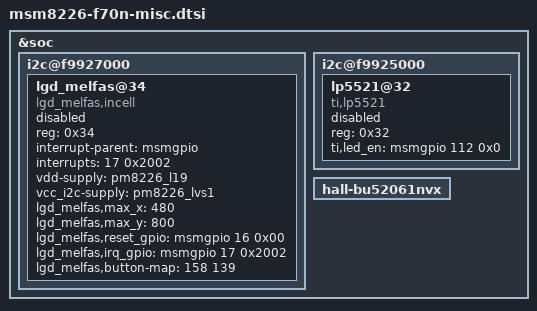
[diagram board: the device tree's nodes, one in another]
/* Copyright (c) 2012, Code Aurora Forum. All rights reserved.
 *
 * This program is free software; you can redistribute it and/or modify
 * it under the terms of the GNU General Public License version 2 and
 * only version 2 as published by the Free Software Foundation.
 *
 * This program is distributed in the hope that it will be useful,
 * but WITHOUT ANY WARRANTY; without even the implied warranty of
 * MERCHANTABILITY or FITNESS FOR A PARTICULAR PURPOSE.  See the
 * GNU General Public License for more details.
 */

&soc {
	i2c@f9927000 { /* BLSP1 QUP5 */
		lgd_melfas@34 {
			compatible = "lgd_melfas,incell";
			reg = <0x34>;
			interrupt-parent = <&msmgpio>;
			interrupts = <17 0x2002>;
			vdd-supply = <&pm8226_l19>;
			vcc_i2c-supply = <&pm8226_lvs1>;
			lgd_melfas,max_x = <480>;
			lgd_melfas,max_y = <800>;
			lgd_melfas,reset_gpio = <&msmgpio 16 0x00>;
			lgd_melfas,irq_gpio = <&msmgpio 17 0x2002>;
			lgd_melfas,button-map = <158 139>;
			status = "disable";
		};

	};

	i2c@f9925000 {
		lp5521@32 {
			compatible = "ti,lp5521";
			status = "disable";
			reg = <0x32>;
			ti,led_en = <&msmgpio 112 0x0>;
		};
	};

	hall-bu52061nvx {
		status = "ok";
	};

};
